# ARMv8M-Baseline register map
Registers are read-only, no defined reset value unless marked. A register's access mark holds for its fields unless they carry their own. Offsets are from the block's base; [hi:lo] are bit positions.

## DCB — Debug Control Block
Base 0xE000EDF0
0x00 DHCSR rw — Debug Halting Control and Status Register controls Halting debug
  [26] S_RESTART_ST — Restart sticky status. Indicates the PE has processed a request to clear DHCSR.C_HALT to 0
    0=PE has not left Debug state since the last read of DHCSR; 1=PE has left Debug state since the last read of DHCSR
  [25] S_RESET_ST — Reset sticky status. Indicates whether the PE has been reset since the last read of the DHCSR
    0=No reset since last DHCSR read; 1=At least one reset since last DHCSR read
  [24] S_RETIRE_ST — Retire sticky status. Set to 1 every time the PE retires one of more instructions
    0=No instruction retired since last DHCSR read; 1=At least one instruction retired since last DHCSR read
  [20] S_SDE — Secure debug enabled. Indicates whether Secure invasive debug is allowed
    0=Secure invasive debug prohibited; 1=Secure invasive debug allowed
  [19] S_LOCKUP — Lockup status. Indicates whether the PE is in Lockup state
    0=Not locked up; 1=Locked up
  [18] S_SLEEP — Sleeping status. Indicates whether the PE is sleeping
    0=Not sleeping; 1=Sleeping
  [17] S_HALT — Halted status. Indicates whether the PE is in Debug state
    0=In Non-debug state; 1=In Debug state
  [31:16] DBGKEY — Debug key
    0xA05F=Writes accompanied by this value update bits[15:0]
  [16] S_REGRDY — Register ready status. Handshake flag to transfers through the DCRDR
    0=Write to DCRSR performed, but transfer not yet complete; 1=Transfer complete, or no outstanding transfer
  [5] C_SNAPSTALL — Snap stall control. Allow imprecise entry to Debug state
    0=No action; 1=Allow imprecise entry to Debug state, for example by forcing any stalled load or store instruction to be abandoned
  [3] C_MASKINTS — Mask interrupts control
    0=Do not mask; 1=Mask PendSV, SysTick and external configurable interrupts
  [2] C_STEP — Step control. Enable single instruction step
    0=No effect; 1=Single step enabled
  [1] C_HALT — Halt control. PE enter Debug state halt request
    0=Causes the PE to leave Debug state, if in Debug state; 1=Halt the PE
  [0] C_DEBUGEN — Debug enable control. Enable Halting debug
    0=Disabled; 1=Enabled
0x04 DCRSR wo — Debug Core Register Select Register provides debug access to the general-purpose registers, special-purpose registers, and the FP extension registers
  [16] REGWnR — Register write/not-read. Specifies the access type for the transfer
    0=Read; 1=Write
  [23:8] If the Main Extension is not implemented — 0b0011000 Non-secure main stack pointer, MSP_NS
  [23:8] If the Main Extension is not implemented — the Security Extension is not implemented, this value is reserved
  [23:8] If the Main Extension is not implemented — the Security Extension is not implemented, this value is reserved
  [6:0] REGSEL — Register selector
0x08 DCRDR rw — Debug Core Register Data Register provides debug access to the general-purpose registers, special-purpose registers, and the FP Extension registers
  [31:0] DBGTMP — Data temporary buffer
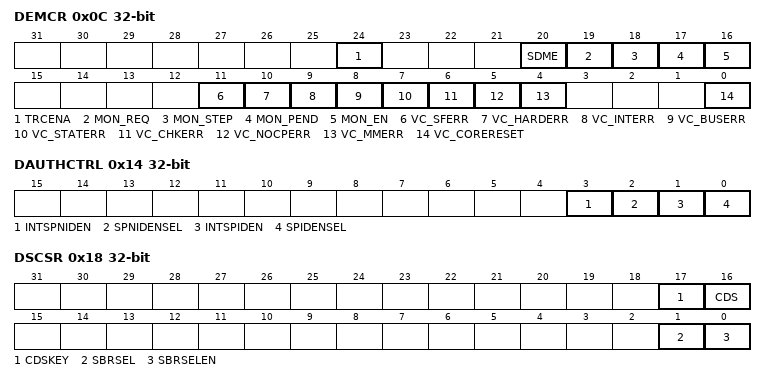
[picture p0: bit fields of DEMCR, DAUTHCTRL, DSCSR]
0x0C DEMCR rw — Debug Exception and Monitor Control Register manages vector catch behavior and DebugMonitor handling when debugging
  [24] TRCENA — Trace enable. Global enable for all DWT and ITM features
    0=DWT and ITM features disabled; 1=DWT and ITM features enabled
  [20] SDME — Secure DebugMonitor enable
    0=Debug events prohibited in Secure state and the DebugMonitor exception targets Non-secure state; 1=Debug events allowed in Secure state and the DebugMonitor exception targets Secure state
  [19] MON_REQ — Monitor request. DebugMonitor semaphore bit
  [18] MON_STEP — Monitor step. Enable DebugMonitor stepping
    0=Stepping disabled; 1=Stepping enabled
  [17] MON_PEND — Monitor pend. Sets or clears the pending state of the DebugMonitor exception
    0=Clear the status of the DebugMonitor exception to not pending; 1=Set the status of the DebugMonitor exception to pending
  [16] MON_EN — Monitor enable. Enable the DebugMonitor exception
    0=DebugMonitor exception disabled; 1=DebugMonitor exception enabled
  [11] VC_SFERR — Vector Catch SecureFault. SecureFault exception Halting debug vector catch enable
    0=Halting debug trap on SecureFault disabled; 1=Halting debug trap on SecureFault enabled
  [10] VC_HARDERR — Vector Catch HardFault errors. HardFault exception Halting debug vector catch enable
    0=Halting debug trap on HardFault disabled; 1=Halting debug trap on HardFault enabled
  [9] VC_INTERR — Vector Catch interrupt errors
    0=Halting debug trap on faults during exception entry and return disabled; 1=Halting debug trap on faults during exception entry and return enabled
  [8] VC_BUSERR — Vector Catch BusFault errors. BusFault exception Halting debug vector catch enable
    0=Halting debug trap on BusFault disabled; 1=Halting debug trap on BusFault enabled
  [7] VC_STATERR — Vector Catch state errors
    0=Halting debug trap on UsageFault caused by state information error disabled; 1=Halting debug trap on UsageFault caused by state information error enabled
  [6] VC_CHKERR — Vector Catch check errors
    0=Halting debug trap on UsageFault caused by checking error disabled; 1=Halting debug trap on UsageFault caused by checking error enabled
  [5] VC_NOCPERR — Vector Catch NOCP errors
    0=Halting debug trap on UsageFault caused by access to a coprocessor disabled; 1=Halting debug trap on UsageFault caused by access to a coprocessor enabled
  [4] VC_MMERR — Vector Catch MemManage errors. Enable Halting debug trap on a MemManage exception
    0=Halting debug trap on MemManage disabled; 1=Halting debug trap on MemManage enabled
  [0] VC_CORERESET — Vector Catch core reset. Enable Reset Vector Catch
    0=Halting debug trap on reset disabled; 1=Halting debug trap on reset enabled
0x14 DAUTHCTRL rw — Debug Authentication Control Register this register allows the IMPLEMENTATION DEFINED authentication interface to be overridden from software
  [3] INTSPNIDEN — Internal Secure non-invasive debug enable
    0=Secure Non-invasive debug prohibited; 1=Secure Non-invasive debug allowed
  [2] SPNIDENSEL — Secure non-invasive debug enable select
    0=Secure non-invasive debug controlled by the IMPLEMENTATION DEFINED external authentication interface
  [1] INTSPIDEN — Internal Secure invasive debug enable
    0=Secure halting and self-hosted debug prohibited; 1=Secure halting and self-hosted debug allowed
  [0] SPIDENSEL — Secure invasive debug enable select
    0=Secure halting and self-hosted debug controlled by the IMPLEMENTATION DEFINED external authentication interface
0x18 DSCSR rw — Debug Security Control and Status Register provides control and status information for Secure debug
  [17] CDSKEY — CDS write-enable key
    0=Concurrent write to CDS not ignored; 1=Concurrent write to CDS ignored
  [16] CDS — Current domain Secure. This field indicates the current Security state of the processor
    0=PE is in Non-secure state; 1=PE is in Secure state
  [1] SBRSEL — Secure Banked register select
    0=Selects the Non-secure versions; 1=Selects the Secure versions
  [0] SBRSELEN — Secure Banked register select enable
    0=The current Security state of the PE determines which memory-mapped banked registers are accessed by the debugger; 1=DSCSR
